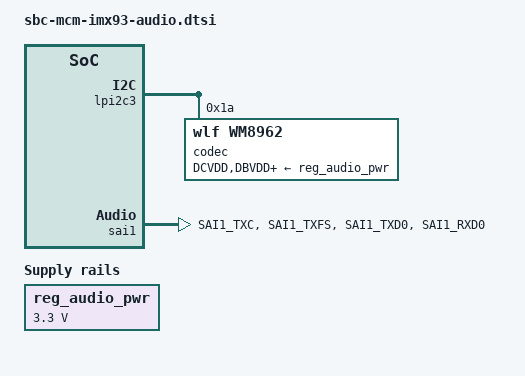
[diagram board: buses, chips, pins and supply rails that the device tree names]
/ {
	reg_audio_pwr: regulator-audio-pwr {
		compatible = "regulator-fixed";
		regulator-name = "audio-pwr";
		regulator-min-microvolt = <3300000>;
		regulator-max-microvolt = <3300000>;
		enable-active-high;
		regulator-always-on;
	};

	sound-wm8962 {
		compatible = "fsl,imx-audio-wm8962x";
		model = "wm8962-audio";
		audio-cpu = <&sai1>;
		audio-codec = <&codec>;
		audio-routing =
			"Headphone Jack", "HPOUTL",
			"Headphone Jack", "HPOUTR",
			"Ext Spk", "SPKOUTL",
			"Ext Spk", "SPKOUTR",
			"AMIC", "MICBIAS",
			"IN3R", "AMIC",
			"IN1R", "AMIC";
	};
};

&lpi2c3 {
	codec: wm8962@1a {
		compatible = "wlf,wm8962";
		reg = <0x1a>;
		clocks = <&clk IMX93_CLK_SAI1_GATE>;
		DCVDD-supply = <&reg_audio_pwr>;
		DBVDD-supply = <&reg_audio_pwr>;
		AVDD-supply = <&reg_audio_pwr>;
		CPVDD-supply = <&reg_audio_pwr>;
		MICVDD-supply = <&reg_audio_pwr>;
		PLLVDD-supply = <&reg_audio_pwr>;
		SPKVDD1-supply = <&reg_audio_pwr>;
		SPKVDD2-supply = <&reg_audio_pwr>;
		gpio-cfg = <
			0x0000 /* 0:Default */
			0x0000 /* 1:Default */
			0x0000 /* 2:FN_DMICCLK */
			0x0000 /* 3:Default */
			0x0000 /* 4:FN_DMICCDAT */
			0x0000 /* 5:Default */
		>;
		status = "okay";
	};
};

&iomuxc {
	pinctrl_sai1: sai1grp {
		fsl,pins = <
			MX93_PAD_SAI1_TXC__SAI1_TX_BCLK			0x31e
			MX93_PAD_SAI1_TXFS__SAI1_TX_SYNC		0x31e
			MX93_PAD_SAI1_TXD0__SAI1_TX_DATA00		0x31e
			MX93_PAD_SAI1_RXD0__SAI1_RX_DATA00		0x31e
		>;
	};
};

&sai1 {
	#sound-dai-cells = <0>;
	pinctrl-names = "default";
	pinctrl-0 = <&pinctrl_sai1>;
	assigned-clocks = <&clk IMX93_CLK_SAI1>;
	assigned-clock-parents = <&clk IMX93_CLK_AUDIO_PLL>;
	assigned-clock-rates = <12288000>;
	fsl,sai-mclk-direction-output;
	status = "okay";
};

